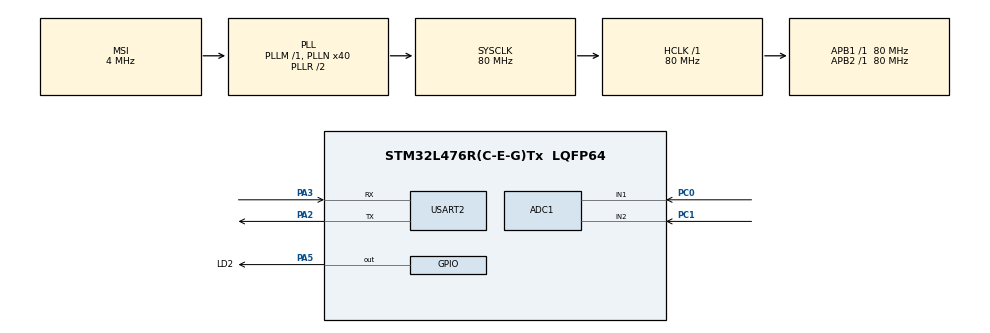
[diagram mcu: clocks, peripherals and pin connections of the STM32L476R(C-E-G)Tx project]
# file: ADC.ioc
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ADC1.Channel-1\#ChannelRegularConversion=ADC_CHANNEL_1
ADC1.Channel-2\#ChannelRegularConversion=ADC_CHANNEL_2
ADC1.ContinuousConvMode=ENABLE
ADC1.DMAContinuousRequests=ENABLE
ADC1.NbrOfConversion=2
ADC1.NbrOfConversionFlag=1
ADC1.OffsetNumber-1\#ChannelRegularConversion=ADC_OFFSET_NONE
ADC1.OffsetNumber-2\#ChannelRegularConversion=ADC_OFFSET_NONE
ADC1.Overrun=ADC_OVR_DATA_OVERWRITTEN
ADC1.OversamplingMode=ENABLE
ADC1.Rank-1\#ChannelRegularConversion=1
ADC1.Rank-2\#ChannelRegularConversion=2
ADC1.Ratio=ADC_OVERSAMPLING_RATIO_16
ADC1.RightBitShift=ADC_RIGHTBITSHIFT_4
ADC1.SamplingTime-1\#ChannelRegularConversion=ADC_SAMPLETIME_640CYCLES_5
ADC1.SamplingTime-2\#ChannelRegularConversion=ADC_SAMPLETIME_640CYCLES_5
ADC1.master=1
Dma.ADC1.0.Direction=DMA_PERIPH_TO_MEMORY
Dma.ADC1.0.Instance=DMA1_Channel1
Dma.ADC1.0.MemDataAlignment=DMA_MDATAALIGN_HALFWORD
Dma.ADC1.0.MemInc=DMA_MINC_ENABLE
Dma.ADC1.0.Mode=DMA_CIRCULAR
Dma.ADC1.0.PeriphDataAlignment=DMA_PDATAALIGN_HALFWORD
Dma.ADC1.0.PeriphInc=DMA_PINC_DISABLE
Dma.ADC1.0.Priority=DMA_PRIORITY_LOW
Dma.Request0=ADC1
Mcu.Family=STM32L4
Mcu.Name=STM32L476R(C-E-G)Tx
Mcu.Package=LQFP64
NVIC.DMA1_Channel1_IRQn=true\:2\:0\:true\:false\:true\:false\:true\:true
NVIC.PriorityGroup=NVIC_PRIORITYGROUP_4
PA13\ (JTMS-SWDIO).Mode=Serial_Wire
PA13\ (JTMS-SWDIO).Signal=SYS_JTMS-SWDIO
PA14\ (JTCK-SWCLK).Mode=Serial_Wire
PA14\ (JTCK-SWCLK).Signal=SYS_JTCK-SWCLK
PA2.Mode=Asynchronous
PA2.Signal=USART2_TX
PA3.Mode=Asynchronous
PA3.Signal=USART2_RX
PA5.GPIO_Label=LD2
PA5.Signal=GPIO_Output
PC0.Signal=ADCx_IN1
PC1.Signal=ADCx_IN2
ProjectManager.HeapSize=0x200
ProjectManager.StackSize=0x400
ProjectManager.TargetToolchain=STM32CubeIDE
RCC.ADCFreq_Value=32000000
RCC.AHBFreq_Value=80000000
RCC.APB1Freq_Value=80000000
RCC.APB1TimFreq_Value=80000000
RCC.APB2Freq_Value=80000000
RCC.APB2TimFreq_Value=80000000
RCC.CortexFreq_Value=80000000
RCC.HCLKFreq_Value=80000000
RCC.HSE_VALUE=8000000
RCC.HSI_VALUE=16000000
RCC.LSE_VALUE=32768
RCC.MSI_VALUE=4000000
RCC.PLLN=40
RCC.PLLSAI1N=16
RCC.SYSCLKFreq_VALUE=80000000
RCC.SYSCLKSource=RCC_SYSCLKSOURCE_PLLCLK
RCC.USBFreq_Value=32000000
RCC.VCOOutputFreq_Value=160000000
SH.ADCx_IN1.0=ADC1_IN1,IN1-Single-Ended
SH.ADCx_IN2.0=ADC1_IN2,IN2-Single-Ended
USART2.VirtualMode-Asynchronous=VM_ASYNC
board=custom

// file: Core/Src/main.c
/* USER CODE BEGIN Header */
/**
  ******************************************************************************
  * @file           : main.c
  * @brief          : Main program body
  ******************************************************************************
  * @attention
  *
  * Copyright (c) 2022 STMicroelectronics.
  * All rights reserved.
  *
  * This software is licensed under terms that can be found in the LICENSE file
  * in the root directory of this software component.
  * If no LICENSE file comes with this software, it is provided AS-IS.
  *
  ******************************************************************************
  */
/* USER CODE END Header */
#include "main.h"
#include "adc.h"
#include "dma.h"
#include "usart.h"
#include "gpio.h"

/* USER CODE BEGIN Includes */
#include <stdio.h>
#include <string.h>
#include <stdbool.h>
/* USER CODE END Includes */

volatile static uint16_t joystick[2];

void SystemClock_Config(void);

/* USER CODE BEGIN 0 */

int __io_putchar(int ch)
{
	if ( ch=='\n')
	{
		uint8_t ch2 = '\r';
		HAL_UART_Transmit(&huart2, (uint8_t*)&ch2, 1, HAL_MAX_DELAY);
	}
	HAL_UART_Transmit(&huart2, (uint8_t*)&ch, 1, HAL_MAX_DELAY);
	return 1;
}

/* USER CODE END 0 */

int main(void)
{

  /* MCU Configuration--------------------------------------------------------*/

  /* Reset of all peripherals, Initializes the Flash interface and the Systick. */
  HAL_Init();

  /* Configure the system clock */
  SystemClock_Config();

  /* Initialize all configured peripherals */
  MX_GPIO_Init();
  MX_DMA_Init();
  MX_USART2_UART_Init();
  MX_ADC1_Init();

  /* Infinite loop */
  /* USER CODE BEGIN WHILE */
//  volatile static uint16_t value[2];

  HAL_ADCEx_Calibration_Start(&hadc1, ADC_SINGLE_ENDED);
  HAL_ADC_Start_DMA(&hadc1, (uint32_t*)joystick, 2);
//  HAL_ADC_Start(&hadc1);
  while (1)
  {

//	  float voltage = 3.3f * (value / 4096.0f);

//	  printf("ADC = %lu (%.3f [V])\n", value, voltage);

	  printf("VRx=%lu, VRy=%lu\n", joystick[0], joystick[1]);

	  HAL_Delay(100);

    /* USER CODE END WHILE */

  }
}

void SystemClock_Config(void)
{
  RCC_OscInitTypeDef RCC_OscInitStruct = {0};
  RCC_ClkInitTypeDef RCC_ClkInitStruct = {0};

  /** Configure the main internal regulator output voltage
  */
  if (HAL_PWREx_ControlVoltageScaling(PWR_REGULATOR_VOLTAGE_SCALE1) != HAL_OK)
  {
    Error_Handler();
  }

  /** Initializes the RCC Oscillators according to the specified parameters
  * in the RCC_OscInitTypeDef structure.
  */
  RCC_OscInitStruct.OscillatorType = RCC_OSCILLATORTYPE_MSI;
  RCC_OscInitStruct.MSIState = RCC_MSI_ON;
  RCC_OscInitStruct.MSICalibrationValue = 0;
  RCC_OscInitStruct.MSIClockRange = RCC_MSIRANGE_6;
  RCC_OscInitStruct.PLL.PLLState = RCC_PLL_ON;
  RCC_OscInitStruct.PLL.PLLSource = RCC_PLLSOURCE_MSI;
  RCC_OscInitStruct.PLL.PLLM = 1;
  RCC_OscInitStruct.PLL.PLLN = 40;
  RCC_OscInitStruct.PLL.PLLP = RCC_PLLP_DIV7;
  RCC_OscInitStruct.PLL.PLLQ = RCC_PLLQ_DIV2;
  RCC_OscInitStruct.PLL.PLLR = RCC_PLLR_DIV2;
  if (HAL_RCC_OscConfig(&RCC_OscInitStruct) != HAL_OK)
  {
    Error_Handler();
  }

  /** Initializes the CPU, AHB and APB buses clocks
  */
  RCC_ClkInitStruct.ClockType = RCC_CLOCKTYPE_HCLK|RCC_CLOCKTYPE_SYSCLK
                              |RCC_CLOCKTYPE_PCLK1|RCC_CLOCKTYPE_PCLK2;
  RCC_ClkInitStruct.SYSCLKSource = RCC_SYSCLKSOURCE_PLLCLK;
  RCC_ClkInitStruct.AHBCLKDivider = RCC_SYSCLK_DIV1;
  RCC_ClkInitStruct.APB1CLKDivider = RCC_HCLK_DIV1;
  RCC_ClkInitStruct.APB2CLKDivider = RCC_HCLK_DIV1;

  if (HAL_RCC_ClockConfig(&RCC_ClkInitStruct, FLASH_LATENCY_4) != HAL_OK)
  {
    Error_Handler();
  }
}

void Error_Handler(void)
{
  __disable_irq();
  while (1)
  {
  }
}
